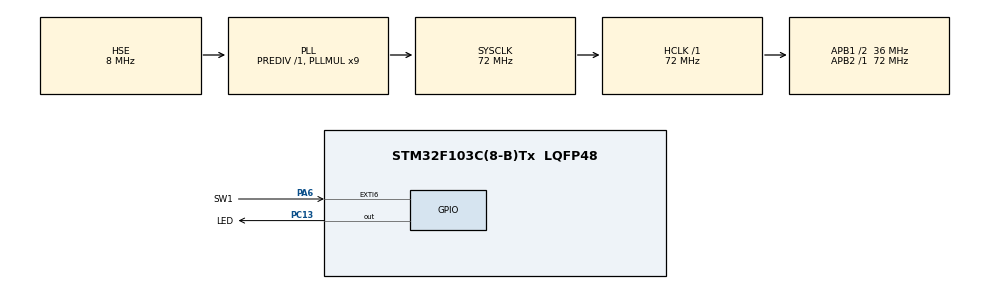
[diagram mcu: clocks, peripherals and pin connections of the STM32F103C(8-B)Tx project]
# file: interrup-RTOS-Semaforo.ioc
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Mcu.Family=STM32F1
RCC.PLLSourceVirtual=RCC_PLLSOURCE_HSE
PA6.GPIO_ModeDefaultEXTI=GPIO_MODE_IT_FALLING
PD1-OSC_OUT.Mode=HSE-External-Oscillator
PC13-TAMPER-RTC.Signal=GPIO_Output
PA6.GPIO_Label=SW1
NVIC.TIM1_UP_IRQn=true\:0\:0\:false\:false\:true\:false\:true
PD0-OSC_IN.Signal=RCC_OSC_IN
RCC.APB1CLKDivider=RCC_HCLK_DIV2
RCC.SYSCLKSource=RCC_SYSCLKSOURCE_PLLCLK
ProjectManager.StackSize=0x400
PD1-OSC_OUT.Signal=RCC_OSC_OUT
PA13.Signal=SYS_JTMS-SWDIO
ProjectManager.TargetToolchain=STM32CubeIDE
RCC.HCLKFreq_Value=72000000
RCC.APB2TimFreq_Value=72000000
RCC.USBFreq_Value=72000000
RCC.AHBFreq_Value=72000000
PD0-OSC_IN.Mode=HSE-External-Oscillator
board=custom
RCC.PLLMUL=RCC_PLL_MUL9
PC13-TAMPER-RTC.GPIO_Label=LED
RCC.APB2Freq_Value=72000000
PA6.GPIO_PuPd=GPIO_PULLUP
PA14.Mode=Serial_Wire
VP_SYS_VS_tim1.Mode=TIM1
PA13.Mode=Serial_Wire
Mcu.Name=STM32F103C(8-B)Tx
RCC.SYSCLKFreq_VALUE=72000000
Mcu.Package=LQFP48
PA6.Signal=GPXTI6
NVIC.TimeBase=TIM1_UP_IRQn
NVIC.EXTI9_5_IRQn=true\:0\:0\:false\:false\:true\:true\:true
NVIC.TimeBaseIP=TIM1
PA14.Signal=SYS_JTCK-SWCLK
ProjectManager.HeapSize=0x200
NVIC.PriorityGroup=NVIC_PRIORITYGROUP_4
RCC.APB1TimFreq_Value=72000000
RCC.APB1Freq_Value=36000000

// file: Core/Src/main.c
/* USER CODE BEGIN Header */
/**
  ******************************************************************************
  * @file           : main.c
  * @brief          : Main program body
  ******************************************************************************
  * @attention
  *
  * <h2><center>&copy; Copyright (c) 2024 STMicroelectronics.
  * All rights reserved.</center></h2>
  *
  * This software component is licensed by ST under BSD 3-Clause license,
  * the "License"; You may not use this file except in compliance with the
  * License. You may obtain a copy of the License at:
  *                        opensource.org/licenses/BSD-3-Clause
  *
  ******************************************************************************
  */
/* USER CODE END Header */
#include "main.h"

/* USER CODE BEGIN Includes */
#include "FreeRTOS.h"
#include "task.h"
//#include "queue.h"
#include "semphr.h"
/* USER CODE END Includes */

/* USER CODE BEGIN PD */
int read_sw1_state = 0;
SemaphoreHandle_t my_semph1;
/* USER CODE END PD */

void SystemClock_Config(void);
static void MX_GPIO_Init(void);

/* USER CODE BEGIN 0 */
static void LedBlink2(void *pvParameters){
	//uint32_t sw1_state = 0;
	while(1){
		/* Se usa el semáforo para esperar por el evento. El semáforo fue creado antes
		que se inicie el scheduler, por lo tanto, antes que esta tarea se ejecute por pri
		mera vez. La tarea se bloquea indefinidamente, por lo que la función saldrá del
		estado bloqueado recién cuando el semáforo este disponible. Por lo tanto, no hay
		necesidad de chequear por el valor de retorno de la función. */
		xSemaphoreTake(my_semph1, portMAX_DELAY);
		HAL_GPIO_WritePin(LED_GPIO_Port, LED_Pin, GPIO_PIN_SET);
		HAL_Delay(500);
 		HAL_GPIO_WritePin(LED_GPIO_Port, LED_Pin, GPIO_PIN_RESET);
 		HAL_Delay(500);
 		HAL_GPIO_WritePin(LED_GPIO_Port, LED_Pin, GPIO_PIN_SET);
		HAL_Delay(500);
		HAL_GPIO_WritePin(LED_GPIO_Port, LED_Pin, GPIO_PIN_RESET);
		HAL_Delay(500);
	}
}

static void LedBlink1(void *pvParameters){
	//uint32_t read_sw1_state;
	while(1){
		HAL_GPIO_WritePin(LED_GPIO_Port, LED_Pin, GPIO_PIN_SET);
		HAL_Delay(100);
 		HAL_GPIO_WritePin(LED_GPIO_Port, LED_Pin, GPIO_PIN_RESET);
 		HAL_Delay(100);
 		//vTaskDelay(100/portTICK_PERIOD_MS); //recordar que sale de la tarea si lo uso.
	}
}
/* USER CODE END 0 */

int main(void)
{

  /* MCU Configuration--------------------------------------------------------*/

  /* Reset of all peripherals, Initializes the Flash interface and the Systick. */
  HAL_Init();

  /* Configure the system clock */
  SystemClock_Config();

  /* Initialize all configured peripherals */
  MX_GPIO_Init();
  /* USER CODE BEGIN 2 */
  vSemaphoreCreateBinary(my_semph1);
  //xSemaphoreGive(my_semph1);
  xTaskCreate(LedBlink1, "Blink 1", 100, NULL, 1, NULL);
  xTaskCreate(LedBlink2, "Blink 2", 100, NULL, 2, NULL);
  vTaskStartScheduler();
  /* USER CODE END 2 */

  /* Infinite loop */
  while (1)
  {
	HAL_GPIO_WritePin(LED_GPIO_Port, LED_Pin, GPIO_PIN_SET);
	HAL_Delay(500);
	HAL_GPIO_WritePin(LED_GPIO_Port, LED_Pin, GPIO_PIN_RESET);
	HAL_Delay(500);
  }
}

void SystemClock_Config(void)
{
  RCC_OscInitTypeDef RCC_OscInitStruct = {0};
  RCC_ClkInitTypeDef RCC_ClkInitStruct = {0};

  /** Initializes the RCC Oscillators according to the specified parameters
  * in the RCC_OscInitTypeDef structure.
  */
  RCC_OscInitStruct.OscillatorType = RCC_OSCILLATORTYPE_HSE;
  RCC_OscInitStruct.HSEState = RCC_HSE_ON;
  RCC_OscInitStruct.HSEPredivValue = RCC_HSE_PREDIV_DIV1;
  RCC_OscInitStruct.HSIState = RCC_HSI_ON;
  RCC_OscInitStruct.PLL.PLLState = RCC_PLL_ON;
  RCC_OscInitStruct.PLL.PLLSource = RCC_PLLSOURCE_HSE;
  RCC_OscInitStruct.PLL.PLLMUL = RCC_PLL_MUL9;
  if (HAL_RCC_OscConfig(&RCC_OscInitStruct) != HAL_OK)
  {
    Error_Handler();
  }
  /** Initializes the CPU, AHB and APB buses clocks
  */
  RCC_ClkInitStruct.ClockType = RCC_CLOCKTYPE_HCLK|RCC_CLOCKTYPE_SYSCLK
                              |RCC_CLOCKTYPE_PCLK1|RCC_CLOCKTYPE_PCLK2;
  RCC_ClkInitStruct.SYSCLKSource = RCC_SYSCLKSOURCE_PLLCLK;
  RCC_ClkInitStruct.AHBCLKDivider = RCC_SYSCLK_DIV1;
  RCC_ClkInitStruct.APB1CLKDivider = RCC_HCLK_DIV2;
  RCC_ClkInitStruct.APB2CLKDivider = RCC_HCLK_DIV1;

  if (HAL_RCC_ClockConfig(&RCC_ClkInitStruct, FLASH_LATENCY_2) != HAL_OK)
  {
    Error_Handler();
  }
}

static void MX_GPIO_Init(void)
{
  GPIO_InitTypeDef GPIO_InitStruct = {0};

  /* GPIO Ports Clock Enable */
  __HAL_RCC_GPIOC_CLK_ENABLE();
  __HAL_RCC_GPIOD_CLK_ENABLE();
  __HAL_RCC_GPIOA_CLK_ENABLE();

  /*Configure GPIO pin Output Level */
  HAL_GPIO_WritePin(LED_GPIO_Port, LED_Pin, GPIO_PIN_RESET);

  /*Configure GPIO pin : LED_Pin */
  GPIO_InitStruct.Pin = LED_Pin;
  GPIO_InitStruct.Mode = GPIO_MODE_OUTPUT_PP;
  GPIO_InitStruct.Pull = GPIO_NOPULL;
  GPIO_InitStruct.Speed = GPIO_SPEED_FREQ_LOW;
  HAL_GPIO_Init(LED_GPIO_Port, &GPIO_InitStruct);

  /*Configure GPIO pin : SW1_Pin */
  GPIO_InitStruct.Pin = SW1_Pin;
  GPIO_InitStruct.Mode = GPIO_MODE_IT_FALLING;
  GPIO_InitStruct.Pull = GPIO_PULLUP;
  HAL_GPIO_Init(SW1_GPIO_Port, &GPIO_InitStruct);

  /* EXTI interrupt init*/
  HAL_NVIC_SetPriority(EXTI9_5_IRQn, 0, 0);
  HAL_NVIC_EnableIRQ(EXTI9_5_IRQn);

}

/* USER CODE BEGIN 4 */
void HAL_GPIO_EXTI_Callback(uint16_t GPIO_Pin)
{
	//if(read_sw1_state) read_sw1_state = 0;
	//else read_sw1_state = 1;
	xSemaphoreGiveFromISR(my_semph1, pdTRUE); //rompe....
	//xSemaphoreGive(my_semph1);
	//HAL_GPIO_ReadPin(SW1_GPIO_Port, SW1_Pin);
}
/* USER CODE END 4 */

 /**
  * @brief  Period elapsed callback in non blocking mode
  * @note   This function is called  when TIM1 interrupt took place, inside
  * HAL_TIM_IRQHandler(). It makes a direct call to HAL_IncTick() to increment
  * a global variable "uwTick" used as application time base.
  * @param  htim : TIM handle
  * @retval None
  */
void HAL_TIM_PeriodElapsedCallback(TIM_HandleTypeDef *htim)
{
  if (htim->Instance == TIM1) {
    HAL_IncTick();
  }
}

void Error_Handler(void)
{
  __disable_irq();
  while (1)
  {
  }
}

/************************ (C) COPYRIGHT STMicroelectronics *****END OF FILE****/
